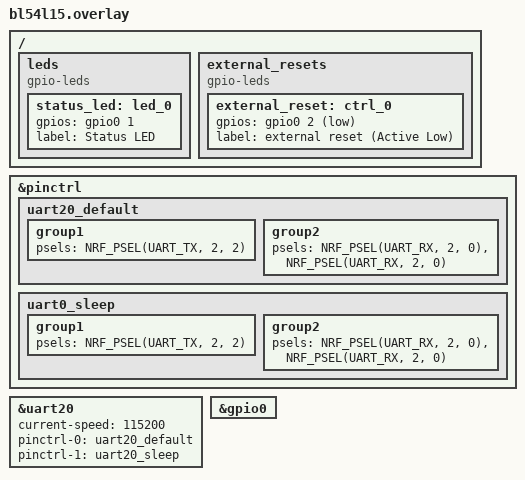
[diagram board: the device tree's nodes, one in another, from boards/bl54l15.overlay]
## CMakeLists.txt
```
cmake_minimum_required(VERSION 3.20.0)
find_package(Zephyr REQUIRED HINTS $ENV{ZEPHYR_BASE})

project(02_DebuggerFirmware)

target_sources(app PRIVATE src/main.c)
target_sources(app PRIVATE src/Services.h src/Services.c)
```

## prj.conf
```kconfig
# Debug output
CONFIG_PRINTK=y
CONFIG_CBPRINTF_FP_SUPPORT=y
CONFIG_LOG=y
CONFIG_LOG_DEFAULT_LEVEL=1

# Debug output via Segger RTT
CONFIG_USE_SEGGER_RTT=y
CONFIG_RTT_CONSOLE=y
CONFIG_LOG_BACKEND_RTT=y

# BLE
CONFIG_BT=y
CONFIG_BT_PERIPHERAL=y
CONFIG_BT_DEVICE_NAME="Micro Mouse Debugger"
CONFIG_BT_ID_MAX=1
CONFIG_BT_PRIVACY=n
# BLE buffersizes etc
CONFIG_BT_USER_DATA_LEN_UPDATE=y
CONFIG_BT_CTLR_DATA_LENGTH_MAX=251
CONFIG_BT_BUF_ACL_RX_SIZE=251
CONFIG_BT_BUF_ACL_TX_SIZE=251
CONFIG_BT_L2CAP_TX_MTU=247

CONFIG_BT_SMP=n # 'y' to enable encrypted communication

CONFIG_BT_HCI_TX_STACK_SIZE_WITH_PROMPT=y
CONFIG_BT_HCI_TX_STACK_SIZE=4096
CONFIG_BT_RX_STACK_SIZE=4096

# UART
CONFIG_SERIAL=y
CONFIG_UART_ASYNC_API=n

# GPIO
CONFIG_GPIO=y

# Increase stack size for the main thread and System Workqueue
CONFIG_SYSTEM_WORKQUEUE_STACK_SIZE=4096
CONFIG_MAIN_STACK_SIZE=4096

# Heap
CONFIG_HEAP_MEM_POOL_SIZE=256
# Flash for program storage
CONFIG_FLASH=y
CONFIG_FLASH_MAP=y
CONFIG_ZMS=y

# Clock
CONFIG_CLOCK_CONTROL_NRF_K32SRC_RC=y
```

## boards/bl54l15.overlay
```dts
&pinctrl {
    uart20_default: uart20_default {
        group1 {
            psels = <NRF_PSEL(UART_TX, 2, 2)>;
        };
        group2 {
            psels = <NRF_PSEL(UART_RX, 2, 0)>, <NRF_PSEL(UART_RX, 2, 0)>; /* somehow only works if defined like this */
        };
    };

    uart0_sleep: uart0_sleep {
        group1 {
            psels = <NRF_PSEL(UART_TX, 2, 2)>;
        };
        group2 {
            psels = <NRF_PSEL(UART_RX, 2, 0)>, <NRF_PSEL(UART_RX, 2, 0)>;
        };
    };
};

&uart20 {
    status = "okay";
    current-speed = <115200>;
    pinctrl-0 = <&uart20_default>;
    pinctrl-1 = <&uart20_sleep>;
    pinctrl-names = "default", "sleep";
};

&gpio0 {
    status = "okay";
};

 / {
    leds {
        compatible = "gpio-leds";
        status_led: led_0 {
            gpios = <&gpio0 1 GPIO_ACTIVE_HIGH>;  /* P0.01 */
            label = "Status LED";
        };
    };

    external_resets {
        compatible = "gpio-leds";
        external_reset: ctrl_0 {
            gpios = <&gpio0 2 GPIO_ACTIVE_LOW>;  /* P0.02 */
            label = "external reset (Active Low)";
        };
    };
};
```

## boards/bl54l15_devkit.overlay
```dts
&pinctrl {
    uart20_default: uart20_default {
        group1 {
            psels = <NRF_PSEL(UART_TX, 1, 8)>;
        };

        group2 {
            psels = <NRF_PSEL(UART_RX, 1, 9)>, <NRF_PSEL(UART_RX, 1, 9)>;
        };
    };

    uart20_sleep: uart20_sleep {
        group1 {
            psels = <NRF_PSEL(UART_TX, 1, 8)>,
                    <NRF_PSEL(UART_RX, 1, 9)>;
        };
    };
};

&uart20 {
    status = "okay";
    current-speed = <9600>;
    pinctrl-0 = <&uart20_default>;
    pinctrl-1 = <&uart20_sleep>;
    pinctrl-names = "default", "sleep";
};

&gpio0 {
    status = "okay";
};

 / {
    leds {
        compatible = "gpio-leds";
        status_led: led_0 {
            gpios = <&gpio0 1 GPIO_ACTIVE_HIGH>;  /* P0.01 */
            label = "Status LED";
        };
    };

    external_resets {
        compatible = "gpio-leds";
        external_reset: ctrl_0 {
            gpios = <&gpio0 4 GPIO_ACTIVE_LOW>;  /* P0.04 */
            label = "external reset (Active Low)";
        };
    };
};

/*
&clock {
	status = "okay";
    lfclk {
        clock-source = "lfrc";
    };
};
*/
```

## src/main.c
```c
#include <zephyr/kernel.h>
#include <zephyr/logging/log.h>
#include <zephyr/bluetooth/bluetooth.h>
#include <zephyr/bluetooth/gap.h>
#include <zephyr/bluetooth/uuid.h>
#include <zephyr/bluetooth/conn.h>
#include <zephyr/bluetooth/addr.h>
#include <zephyr/device.h>
#include <zephyr/sys/reboot.h>
#include <stdlib.h>
#include "Services.h"
#include <zephyr/drivers/uart.h>
#include <zephyr/drivers/gpio.h>

#include <zephyr/devicetree.h>

LOG_MODULE_REGISTER(Main, LOG_LEVEL_DBG);

#define DEVICE_NAME CONFIG_BT_DEVICE_NAME
#define DEVICE_NAME_LEN (sizeof(DEVICE_NAME) - 1)

#define ExternalResetTime K_MSEC(250)

static struct FirmwareVersion_t FirmwareVersion = {
	.Major = 1,
	.Minor = 1,
	.Patch = 0
};

static const struct gpio_dt_spec status_led = GPIO_DT_SPEC_GET(DT_ALIAS(led0), gpios);
static const struct gpio_dt_spec external_reset = GPIO_DT_SPEC_GET(DT_PATH(external_resets, ctrl_0), gpios);

const struct device *uart = DEVICE_DT_GET(DT_NODELABEL(uart20));

// --- advertising settings ---
static const struct bt_le_adv_param *adv_param = BT_LE_ADV_PARAM(
	(BT_LE_ADV_OPT_CONN | BT_LE_ADV_OPT_USE_IDENTITY), /* Connectable advertising and use identity address */
	800, /* Min Advertising Interval 500ms (800*0.625ms) */
	801, /* Max Advertising Interval 500.625ms (801*0.625ms) */
	NULL /* Set to NULL for undirected advertising */
);

static struct bt_data ad[] = {
	BT_DATA_BYTES(BT_DATA_FLAGS, (BT_LE_AD_GENERAL | BT_LE_AD_NO_BREDR)),
	BT_DATA(BT_DATA_NAME_COMPLETE, DEVICE_NAME, DEVICE_NAME_LEN),
};

static const struct bt_data sd[] = {
	BT_DATA_BYTES(BT_DATA_UUID128_ALL, BT_UUID_Service_VAL),
};

// --- BLE service callbacks ---
static void SendCommandCB(char* Buffer, uint32_t Length)
{
	LOG_INF("Got command %s", Buffer);

	int ret = uart_tx(uart, Buffer, Length, SYS_FOREVER_US);
	if (ret) {
		LOG_ERR("Failed to send command via uart!");
	}
}

static void DoResetCB()
{
	LOG_INF("Reset Command received!");

	gpio_pin_set_dt(&external_reset, 1);
	k_sleep(ExternalResetTime);
	gpio_pin_set_dt(&external_reset, 0);
}

static struct Service_Callbacks app_callbacks = {
	.set_command_cb = SendCommandCB,
	.do_reset_cb = DoResetCB
};

static void adv_work_handler(struct k_work *work)
{
	int err = bt_le_adv_start(adv_param, ad, ARRAY_SIZE(ad), sd, ARRAY_SIZE(sd));
	if (err) {
		LOG_ERR("Failed to re-enable advertising (err %d)", err);
		return;
	}

	LOG_INF("Advertising successfully started");
}

static struct k_work adv_work;

static void advertising_start(void)
{
	k_work_submit(&adv_work);
}

bool DeviceConnected = false;

// --- connect / disconnect handlers ---
static void on_connected(struct bt_conn *conn, uint8_t err)
{
	if (err) {
		LOG_ERR("Connection failed (err %u)", err);
		return;
	}

	LOG_INF("BLE device connected!");

	//stop advertising after a device is connected
	bt_le_adv_stop(); 

	DeviceConnected = true;
	gpio_pin_set_dt(&status_led, 1);
}

static void on_disconnected(struct bt_conn *conn, uint8_t reason)
{
	LOG_INF("BLE device disconnected (reason %u)", reason);

	gpio_pin_set_dt(&status_led, 0);
	DeviceConnected = false;

	//re-enable advertising after the device has disconnected
	advertising_start();
}

static void on_recycled(void)
{
	LOG_INF("Connection object available from previous conn. Disconnect is complete!\n");
	advertising_start();
}

#ifdef CONFIG_BT_SMP
static void on_security_changed(struct bt_conn *conn, bt_security_t level, enum bt_security_err err)
{
	char addr[BT_ADDR_LE_STR_LEN];

	bt_addr_le_to_str(bt_conn_get_dst(conn), addr, sizeof(addr));

	if (!err) {
		LOG_INF("Security changed: %s level %u", addr, level);
	} else {
		LOG_INF("Security failed: %s level %u err %d", addr, level, err);
	}
}
#endif

struct bt_conn_cb connection_callbacks = {
	.connected = on_connected,
	.disconnected = on_disconnected,
	.recycled = on_recycled,
#ifdef CONFIG_BT_SMP
	.security_changed = on_security_changed,
#endif
};

// --- main ---
int main(void)
{
	int err;
	
	LOG_INF("Starting Micromouse BLE Debugger");

	// initialize gpios
	while (!gpio_is_ready_dt(&status_led)) 
	{
		k_sleep(K_MSEC(100));
	}

	err = gpio_pin_configure_dt(&status_led, GPIO_OUTPUT_INACTIVE);
	if (err)
	{
		LOG_ERR("Failed to initialize status led!");
		return -1;
	}

	while (!gpio_is_ready_dt(&external_reset)) 
	{
		k_sleep(K_MSEC(100));
	}

	err = gpio_pin_configure_dt(&external_reset, GPIO_OUTPUT_INACTIVE);
	if (err)
	{
		LOG_ERR("Failed to initialize external reset!");
		return -1;
	}

	// initialize uart / wait until device is ready
	while(!device_is_ready(uart))
	{
		k_sleep(K_MSEC(100));
	}

	//create static address
	bt_addr_le_t addr;
    err = bt_addr_le_from_str("FF:EE:DD:CC:BB:AA", "random", &addr);
    if (err) {
        LOG_ERR("Invalid BT address (err %d)\n", err);
    }

    err = bt_id_create(&addr, NULL);
    if (err < 0) {
        LOG_ERR("Creating new ID failed (err %d)\n", err);
    }

	// enable / initialize bluetooth
	err = bt_enable(NULL);
	if (err) {
		LOG_ERR("Bluetooth init failed (err %d)", err);
		return -1;
	}
	bt_conn_cb_register(&connection_callbacks);

	// initialize BLE services
	err = Services_init(&app_callbacks, &FirmwareVersion);
	if (err) {
		LOG_ERR("Failed to init bluetooth service (err:%d)", err);
		return -1;
	}

	k_work_init(&adv_work, adv_work_handler);

	LOG_INF("Bluetooth initialized");
    
	// start bluetooth advertising
	advertising_start();

	// --- UART RX (polling) ---

	uint64_t BlinkTS = k_uptime_get();
	uint64_t LastPacketTS = 0;
	#define TimeOutMS 2
	bool isInTimeout = true;

	#define UART_BUF_RX 250
	volatile uint8_t UartBuffer[UART_BUF_RX];
	volatile uint16_t BufferIndex = 0;
	
	while (1) {
        volatile uint8_t byte;

        //try to read one byte
        int ret = uart_poll_in(uart, &byte);
		uint64_t CurrentTS = k_uptime_get();

        if (ret == 0 && BufferIndex < UART_BUF_RX) 
		{
			//-> got a new byte
			isInTimeout = false;
			UartBuffer[BufferIndex++] = byte;
			LastPacketTS = CurrentTS;
        }
		else
		{
			//-> no new byte, or buffer full
			if(!isInTimeout && (CurrentTS - LastPacketTS >= TimeOutMS || BufferIndex >= UART_BUF_RX))
			{
				//send buffer via BLE
				Services_SendDebugNotify(UartBuffer, BufferIndex);
				
				isInTimeout = true; //indicate that buffer was already transmitted via BLE
				BufferIndex = 0;
				
			}
		}

		if(!DeviceConnected)
		{
			//LED blinks when no device is connected -> indicate active BLE advertising
			if(CurrentTS - BlinkTS >= 100)
			{
				gpio_pin_toggle_dt(&status_led);
				BlinkTS = CurrentTS;
			}
		}
    }
}
```

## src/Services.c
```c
#include <zephyr/types.h>
#include <stddef.h>
#include <string.h>
#include <errno.h>
#include <zephyr/sys/printk.h>
#include <zephyr/sys/byteorder.h>
#include <zephyr/kernel.h>
#include <zephyr/logging/log.h>
#include <zephyr/bluetooth/bluetooth.h>
#include <zephyr/bluetooth/hci.h>
#include <zephyr/bluetooth/conn.h>
#include <zephyr/bluetooth/uuid.h>
#include <zephyr/bluetooth/gatt.h>

#include "Services.h"

LOG_MODULE_REGISTER(BLEServices, LOG_LEVEL_DBG);

static volatile bool notify_mysensor_enabled = false;
static struct Service_Callbacks svc_callbacks;
static struct FirmwareVersion_t internal_firmware_version;

// --- forward declarations ---
static ssize_t read_firmware_version(struct bt_conn *conn, const struct bt_gatt_attr *attr, void *buf, uint16_t len, uint16_t offset);

static ssize_t write_command(struct bt_conn *conn, const struct bt_gatt_attr *attr, const void *buf, uint16_t len, uint16_t offset, uint8_t flags);

static ssize_t reset_command(struct bt_conn *conn, const struct bt_gatt_attr *attr, const void *buf, uint16_t len, uint16_t offset, uint8_t flags);

static void config_changed_DebugNotify(const struct bt_gatt_attr *attr, uint16_t value);


// --- service declaration ---

//only use encrypted versions of security management layer is enabled
#ifdef CONFIG_BT_SMP 
	#define CUSTOM_PERM_WRITE BT_GATT_PERM_WRITE_ENCRYPT
	#define CUSTOM_PERM_READ BT_GATT_PERM_READ_ENCRYPT
#else
	#define CUSTOM_PERM_WRITE BT_GATT_PERM_WRITE
	#define CUSTOM_PERM_READ BT_GATT_PERM_READ
#endif

BT_GATT_SERVICE_DEFINE(
	service_definition, BT_GATT_PRIMARY_SERVICE(BT_UUID_Service),

	//Debug notification service (NOTE: index of this entry is used by Services_send_sensor_notify)
	BT_GATT_CHARACTERISTIC(BT_UUID_Service_DebugNotify, BT_GATT_CHRC_NOTIFY, BT_GATT_PERM_NONE, NULL, NULL, NULL),
	//DebugNotify configuration service
	BT_GATT_CCC(config_changed_DebugNotify, CUSTOM_PERM_READ | CUSTOM_PERM_WRITE),

	//Firmware version service
	BT_GATT_CHARACTERISTIC(BT_UUID_Service_FirmwareVersion, BT_GATT_CHRC_READ, CUSTOM_PERM_READ,
					read_firmware_version, NULL, &internal_firmware_version),

	//Device name service
	BT_GATT_CHARACTERISTIC(BT_UUID_Service_SendCommand, BT_GATT_CHRC_WRITE, CUSTOM_PERM_WRITE,
					NULL, write_command, NULL),

	//Reset service
	BT_GATT_CHARACTERISTIC(BT_UUID_Service_Reset, BT_GATT_CHRC_WRITE, CUSTOM_PERM_WRITE,
					NULL, reset_command, NULL),
);

int Services_init(struct Service_Callbacks *callbacks, struct FirmwareVersion_t *FirmwareVersion)
{
	if(callbacks == 0 || FirmwareVersion == 0) return -EFAULT;

	svc_callbacks.set_command_cb = callbacks->set_command_cb;
	svc_callbacks.do_reset_cb = callbacks->do_reset_cb;

	internal_firmware_version.Major = FirmwareVersion->Major;
	internal_firmware_version.Minor = FirmwareVersion->Minor;
	internal_firmware_version.Patch = FirmwareVersion->Patch;

	return 0;
}

int Services_SendDebugNotify(char* DebugMessage, uint16_t size_bytes)
{
	if (!notify_mysensor_enabled) {
		return -EACCES;
	}

	return bt_gatt_notify(NULL, &service_definition.attrs[1], DebugMessage, size_bytes);
}

bool Services_IsSensorNotifyEnabled()
{
    return notify_mysensor_enabled;
}

// --- callbacks ---
//gets called when the firmware version was requested
static ssize_t read_firmware_version(struct bt_conn *conn, const struct bt_gatt_attr *attr, void *buf, uint16_t len, uint16_t offset)
{
	if(conn == 0 || attr == 0 || buf == 0) return BT_GATT_ERR(BT_ATT_ERR_INVALID_HANDLE);

	LOG_DBG("Attribute read, handle: %u, conn: %p", attr->handle, (void *)conn);

	return bt_gatt_attr_read(conn, attr, buf, len, offset, attr->user_data, sizeof(struct FirmwareVersion_t));
}



//gets called when the device name was set
static ssize_t write_command(struct bt_conn *conn, const struct bt_gatt_attr *attr, const void *buf, uint16_t len, uint16_t offset, uint8_t flags)
{
	if(conn == 0 || attr == 0 || buf == 0) return BT_GATT_ERR(BT_ATT_ERR_INVALID_HANDLE);

	LOG_DBG("Attribute write, handle: %u, conn: %p", attr->handle, (void *)conn);

	if(svc_callbacks.set_command_cb != 0) svc_callbacks.set_command_cb(buf, len);

	return len;
}

static ssize_t reset_command(struct bt_conn *conn, const struct bt_gatt_attr *attr, const void *buf, uint16_t len, uint16_t offset, uint8_t flags)
{
	if(conn == 0 || attr == 0 || buf == 0) return BT_GATT_ERR(BT_ATT_ERR_INVALID_HANDLE);

	LOG_DBG("Attribute write, handle: %u, conn: %p", attr->handle, (void *)conn);

	if(svc_callbacks.do_reset_cb != 0) svc_callbacks.do_reset_cb();

	return len;
}

//gets called when the sensor notification configuration was changed (enabled/disabled)
static void config_changed_DebugNotify(const struct bt_gatt_attr *attr, uint16_t value)
{
	notify_mysensor_enabled = (value == BT_GATT_CCC_NOTIFY);
}
```

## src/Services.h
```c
#ifndef BT_Services_H_
#define BT_Services_H_

#ifdef __cplusplus
extern "C" {
#endif

#include <zephyr/types.h>

// --- UUIDs ---
//Service UUID
#define BT_UUID_Service_VAL BT_UUID_128_ENCODE(0x9E150000, 0x2424, 0x3535, 0x4711, 0x0000decafbad)
#define BT_UUID_Service BT_UUID_DECLARE_128(BT_UUID_Service_VAL)

//Firmware version UUID
#define BT_UUID_Service_FirmwareVersion_VAL BT_UUID_128_ENCODE(0x9E150001, 0x2424, 0x3535, 0x4711, 0x0000decafbad)
#define BT_UUID_Service_FirmwareVersion BT_UUID_DECLARE_128(BT_UUID_Service_FirmwareVersion_VAL)

//Send Command UUID
#define BT_UUID_Service_SendCommand_VAL BT_UUID_128_ENCODE(0x9E150002, 0x2424, 0x3535, 0x4711, 0x0000decafbad)
#define BT_UUID_Service_SendCommand BT_UUID_DECLARE_128(BT_UUID_Service_SendCommand_VAL)

//Reset UUID
#define BT_UUID_Service_Reset_VAL BT_UUID_128_ENCODE(0x9E150003, 0x2424, 0x3535, 0x4711, 0x0000decafbad)
#define BT_UUID_Service_Reset BT_UUID_DECLARE_128(BT_UUID_Service_Reset_VAL)

//Debug Notify UUID
#define BT_UUID_Service_DebugNotify_VAL BT_UUID_128_ENCODE(0x9E150004, 0x2424, 0x3535, 0x4711, 0x0000decafbad)
#define BT_UUID_Service_DebugNotify BT_UUID_DECLARE_128(BT_UUID_Service_DebugNotify_VAL)

// --- Callbacks ---

//device name
typedef void (*set_command_cb_t)(char* Buffer, uint32_t Length);
typedef void (*do_reset_cb_t)();

//callback struct used by the service
struct Service_Callbacks {
	set_command_cb_t set_command_cb;
	do_reset_cb_t do_reset_cb;
};

struct FirmwareVersion_t
{
	uint8_t Major;
	uint8_t Minor;
	uint8_t Patch;
};

/// @brief Initializes the service
/// @param callbacks Struct containing callbacks for functionality.
/// @param FirmwareVersion Structu containing the firmware version.
/// @return 0 if operation was successful, an errorcode otherwise.
int Services_init(struct Service_Callbacks *callbacks, struct FirmwareVersion_t *FirmwareVersion);

/// @brief Notifies the subscriber about new debug messages.
/// @param DebugMessage Pointer to debug message.
/// @param size_bytes Size of data to send.
/// @return 0 if operation was successful, an errorcode otherwise.
int Services_SendDebugNotify(char* DebugMessage, uint16_t size_bytes);

/// @brief Check if a client enabled the notify characteristic.
/// @return True if enabled, false otherwise.
bool Services_IsSensorNotifyEnabled();

#ifdef __cplusplus
}
#endif

#endif
```
